# RP2350 register map
Vendor: Raspberry Pi; Series: RP; File version: 0.1
CPU: CM33 r1p0, little endian, MPU, FPU, DSP, VTOR, 4 interrupt priority bits, 52 interrupts, 8 SAU regions
Registers are 32-bit, read-write, reset 0x0 unless marked. A register's access mark holds for its fields unless they carry their own. Offsets are from the block's base; [hi:lo] are bit positions; {n}, {i} and the like mark numbered series.

## ACCESSCTRL (part 1 of 2) — Hardware access control registers
Base 0x40060000
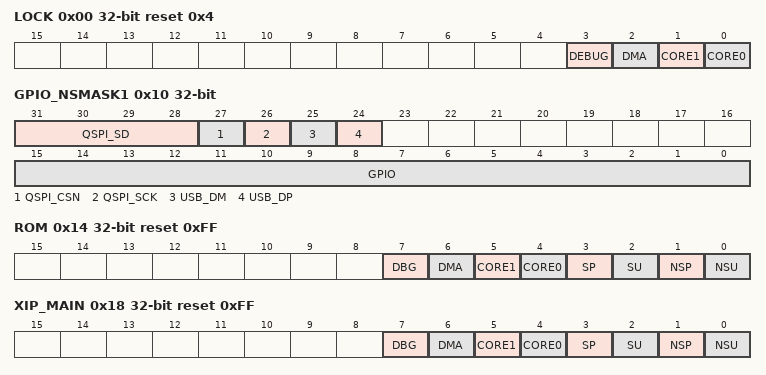
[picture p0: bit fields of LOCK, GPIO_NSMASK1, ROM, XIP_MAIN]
0x00 LOCK reset 0x4 — Once a LOCK bit is written to 1, ACCESSCTRL silently ignores writes from that master. LOCK is writable only by a Secure, Privileged processor or debugger. LOCK bits are only writable when their value is zero. Once set, they can never be cleared, except by a full reset of ACCESSCTRL Setting the LOCK bit does not affect whether an access raises a bus error. Unprivileged writes, or writes from the DMA, will continue to raise bus errors. All other accesses will continue not to.
  [3] DEBUG — Pre-defined description
  [2] DMA ro — Pre-defined description
  [1] CORE1 — Pre-defined description
  [0] CORE0 — Pre-defined description
0x04 FORCE_CORE_NS — Force core 1's bus accesses to always be Non-secure, no matter the core's internal state. Useful for schemes where one core is designated as the Non-secure core, since some peripherals may filter individual registers internally based on security state but not on master ID.
  [1] CORE1 — Pre-defined description
0x08 CFGRESET — Write 1 to reset all ACCESSCTRL configuration, except for the LOCK and FORCE_CORE_NS registers. This bit is used in the RP2350 bootrom to quickly restore ACCESSCTRL to a known state during the boot path. Note that, like all registers in ACCESSCTRL, this register is not writable when the writer's corresponding LOCK bit is set, therefore a master which has been locked out of ACCESSCTRL can not use the CFGRESET register to disturb its contents.
  [0] CFGRESET wo — Pre-defined description
0x0C GPIO_NSMASK0 — Control whether GPIO0...31 are accessible to Non-secure code. Writable only by a Secure, Privileged processor or debugger. 0 -> Secure access only 1 -> Secure + Non-secure access
  [31:0] GPIO_NSMASK0 — Pre-defined description
0x10 GPIO_NSMASK1 — Control whether GPIO32..47 are accessible to Non-secure code, and whether QSPI and USB bitbang are accessible through the Non-secure SIO. Writable only by a Secure, Privileged processor or debugger.
  [31:28] QSPI_SD — Pre-defined description
  [27] QSPI_CSN — Pre-defined description
  [26] QSPI_SCK — Pre-defined description
  [25] USB_DM — Pre-defined description
  [24] USB_DP — Pre-defined description
  [15:0] GPIO — Pre-defined description
0x14 ROM reset 0xFF — Control whether debugger, DMA, core 0 and core 1 can access ROM, and at what security/privilege levels they can do so. Defaults to fully open access. This register is writable only from a Secure, Privileged processor or debugger, with the exception of the NSU bit, which becomes Non-secure-Privileged-writable when the NSP bit is set.
  [7] DBG — If 1, ROM can be accessed by the debugger, at security/privilege levels permitted by SP/NSP/SU/NSU in this register.
  [6] DMA — If 1, ROM can be accessed by the DMA, at security/privilege levels permitted by SP/NSP/SU/NSU in this register.
  [5] CORE1 — If 1, ROM can be accessed by core 1, at security/privilege levels permitted by SP/NSP/SU/NSU in this register.
  [4] CORE0 — If 1, ROM can be accessed by core 0, at security/privilege levels permitted by SP/NSP/SU/NSU in this register.
  [3] SP — If 1, ROM can be accessed from a Secure, Privileged context.
  [2] SU — If 1, and SP is also set, ROM can be accessed from a Secure, Unprivileged context.
  [1] NSP — If 1, ROM can be accessed from a Non-secure, Privileged context.
  [0] NSU — If 1, and NSP is also set, ROM can be accessed from a Non-secure, Unprivileged context. This bit is writable from a Non-secure, Privileged context, if and only if the NSP bit is set.
0x18 XIP_MAIN reset 0xFF — Control whether debugger, DMA, core 0 and core 1 can access XIP_MAIN, and at what security/privilege levels they can do so. Defaults to fully open access. This register is writable only from a Secure, Privileged processor or debugger, with the exception of the NSU bit, which becomes Non-secure-Privileged-writable when the NSP bit is set.
  [7] DBG — If 1, XIP_MAIN can be accessed by the debugger, at security/privilege levels permitted by SP/NSP/SU/NSU in this register.
  [6] DMA — If 1, XIP_MAIN can be accessed by the DMA, at security/privilege levels permitted by SP/NSP/SU/NSU in this register.
  [5] CORE1 — If 1, XIP_MAIN can be accessed by core 1, at security/privilege levels permitted by SP/NSP/SU/NSU in this register.
  [4] CORE0 — If 1, XIP_MAIN can be accessed by core 0, at security/privilege levels permitted by SP/NSP/SU/NSU in this register.
  [3] SP — If 1, XIP_MAIN can be accessed from a Secure, Privileged context.
  [2] SU — If 1, and SP is also set, XIP_MAIN can be accessed from a Secure, Unprivileged context.
  [1] NSP — If 1, XIP_MAIN can be accessed from a Non-secure, Privileged context.
  [0] NSU — If 1, and NSP is also set, XIP_MAIN can be accessed from a Non-secure, Unprivileged context. This bit is writable from a Non-secure, Privileged context, if and only if the NSP bit is set.
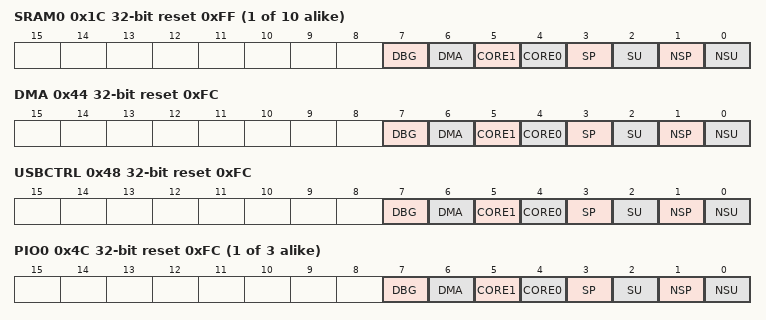
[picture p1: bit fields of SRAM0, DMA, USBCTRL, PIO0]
{0x1C+4i} SRAM{i} reset 0xFF (i=0..9) — Control whether debugger, DMA, core 0 and core 1 can access SRAM{i}, and at what security/privilege levels they can do so. Defaults to fully open access. This register is writable only from a Secure, Privileged processor or debugger, with the exception of the NSU bit, which becomes Non-secure-Privileged-writable when the NSP bit is set.
  [7] DBG — If 1, SRAM{i} can be accessed by the debugger, at security/privilege levels permitted by SP/NSP/SU/NSU in this register.
  [6] DMA — If 1, SRAM{i} can be accessed by the DMA, at security/privilege levels permitted by SP/NSP/SU/NSU in this register.
  [5] CORE1 — If 1, SRAM{i} can be accessed by core 1, at security/privilege levels permitted by SP/NSP/SU/NSU in this register.
  [4] CORE0 — If 1, SRAM{i} can be accessed by core 0, at security/privilege levels permitted by SP/NSP/SU/NSU in this register.
  [3] SP — If 1, SRAM{i} can be accessed from a Secure, Privileged context.
  [2] SU — If 1, and SP is also set, SRAM{i} can be accessed from a Secure, Unprivileged context.
  [1] NSP — If 1, SRAM{i} can be accessed from a Non-secure, Privileged context.
  [0] NSU — If 1, and NSP is also set, SRAM{i} can be accessed from a Non-secure, Unprivileged context. This bit is writable from a Non-secure, Privileged context, if and only if the NSP bit is set.
0x44 DMA reset 0xFC — Control whether debugger, DMA, core 0 and core 1 can access DMA, and at what security/privilege levels they can do so. Defaults to Secure access from any master. This register is writable only from a Secure, Privileged processor or debugger, with the exception of the NSU bit, which becomes Non-secure-Privileged-writable when the NSP bit is set.
  [7] DBG — If 1, DMA can be accessed by the debugger, at security/privilege levels permitted by SP/NSP/SU/NSU in this register.
  [6] DMA — If 1, DMA can be accessed by the DMA, at security/privilege levels permitted by SP/NSP/SU/NSU in this register.
  [5] CORE1 — If 1, DMA can be accessed by core 1, at security/privilege levels permitted by SP/NSP/SU/NSU in this register.
  [4] CORE0 — If 1, DMA can be accessed by core 0, at security/privilege levels permitted by SP/NSP/SU/NSU in this register.
  [3] SP — If 1, DMA can be accessed from a Secure, Privileged context.
  [2] SU — If 1, and SP is also set, DMA can be accessed from a Secure, Unprivileged context.
  [1] NSP — If 1, DMA can be accessed from a Non-secure, Privileged context.
  [0] NSU — If 1, and NSP is also set, DMA can be accessed from a Non-secure, Unprivileged context. This bit is writable from a Non-secure, Privileged context, if and only if the NSP bit is set.
0x48 USBCTRL reset 0xFC — Control whether debugger, DMA, core 0 and core 1 can access USBCTRL, and at what security/privilege levels they can do so. Defaults to Secure access from any master. This register is writable only from a Secure, Privileged processor or debugger, with the exception of the NSU bit, which becomes Non-secure-Privileged-writable when the NSP bit is set.
  [7] DBG — If 1, USBCTRL can be accessed by the debugger, at security/privilege levels permitted by SP/NSP/SU/NSU in this register.
  [6] DMA — If 1, USBCTRL can be accessed by the DMA, at security/privilege levels permitted by SP/NSP/SU/NSU in this register.
  [5] CORE1 — If 1, USBCTRL can be accessed by core 1, at security/privilege levels permitted by SP/NSP/SU/NSU in this register.
  [4] CORE0 — If 1, USBCTRL can be accessed by core 0, at security/privilege levels permitted by SP/NSP/SU/NSU in this register.
  [3] SP — If 1, USBCTRL can be accessed from a Secure, Privileged context.
  [2] SU — If 1, and SP is also set, USBCTRL can be accessed from a Secure, Unprivileged context.
  [1] NSP — If 1, USBCTRL can be accessed from a Non-secure, Privileged context.
  [0] NSU — If 1, and NSP is also set, USBCTRL can be accessed from a Non-secure, Unprivileged context. This bit is writable from a Non-secure, Privileged context, if and only if the NSP bit is set.
{0x4C+4i} PIO{i} reset 0xFC (i=0..2) — Control whether debugger, DMA, core 0 and core 1 can access PIO{i}, and at what security/privilege levels they can do so. Defaults to Secure access from any master. This register is writable only from a Secure, Privileged processor or debugger, with the exception of the NSU bit, which becomes Non-secure-Privileged-writable when the NSP bit is set.
  [7] DBG — If 1, PIO{i} can be accessed by the debugger, at security/privilege levels permitted by SP/NSP/SU/NSU in this register.
  [6] DMA — If 1, PIO{i} can be accessed by the DMA, at security/privilege levels permitted by SP/NSP/SU/NSU in this register.
  [5] CORE1 — If 1, PIO{i} can be accessed by core 1, at security/privilege levels permitted by SP/NSP/SU/NSU in this register.
  [4] CORE0 — If 1, PIO{i} can be accessed by core 0, at security/privilege levels permitted by SP/NSP/SU/NSU in this register.
  [3] SP — If 1, PIO{i} can be accessed from a Secure, Privileged context.
  [2] SU — If 1, and SP is also set, PIO{i} can be accessed from a Secure, Unprivileged context.
  [1] NSP — If 1, PIO{i} can be accessed from a Non-secure, Privileged context.
  [0] NSU — If 1, and NSP is also set, PIO{i} can be accessed from a Non-secure, Unprivileged context. This bit is writable from a Non-secure, Privileged context, if and only if the NSP bit is set.
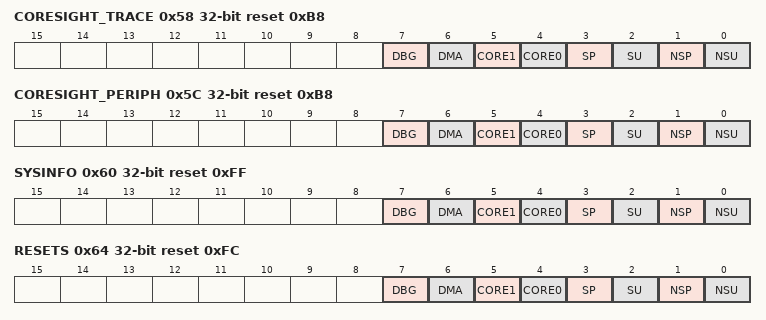
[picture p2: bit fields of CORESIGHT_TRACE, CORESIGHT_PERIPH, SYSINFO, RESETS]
0x58 CORESIGHT_TRACE reset 0xB8 — Control whether debugger, DMA, core 0 and core 1 can access CORESIGHT_TRACE, and at what security/privilege levels they can do so. Defaults to Secure, Privileged processor or debug access only. This register is writable only from a Secure, Privileged processor or debugger, with the exception of the NSU bit, which becomes Non-secure-Privileged-writable when the NSP bit is set.
  [7] DBG — If 1, CORESIGHT_TRACE can be accessed by the debugger, at security/privilege levels permitted by SP/NSP/SU/NSU in this register.
  [6] DMA — If 1, CORESIGHT_TRACE can be accessed by the DMA, at security/privilege levels permitted by SP/NSP/SU/NSU in this register.
  [5] CORE1 — If 1, CORESIGHT_TRACE can be accessed by core 1, at security/privilege levels permitted by SP/NSP/SU/NSU in this register.
  [4] CORE0 — If 1, CORESIGHT_TRACE can be accessed by core 0, at security/privilege levels permitted by SP/NSP/SU/NSU in this register.
  [3] SP — If 1, CORESIGHT_TRACE can be accessed from a Secure, Privileged context.
  [2] SU — If 1, and SP is also set, CORESIGHT_TRACE can be accessed from a Secure, Unprivileged context.
  [1] NSP — If 1, CORESIGHT_TRACE can be accessed from a Non-secure, Privileged context.
  [0] NSU — If 1, and NSP is also set, CORESIGHT_TRACE can be accessed from a Non-secure, Unprivileged context. This bit is writable from a Non-secure, Privileged context, if and only if the NSP bit is set.
0x5C CORESIGHT_PERIPH reset 0xB8 — Control whether debugger, DMA, core 0 and core 1 can access CORESIGHT_PERIPH, and at what security/privilege levels they can do so. Defaults to Secure, Privileged processor or debug access only. This register is writable only from a Secure, Privileged processor or debugger, with the exception of the NSU bit, which becomes Non-secure-Privileged-writable when the NSP bit is set.
  [7] DBG — If 1, CORESIGHT_PERIPH can be accessed by the debugger, at security/privilege levels permitted by SP/NSP/SU/NSU in this register.
  [6] DMA — If 1, CORESIGHT_PERIPH can be accessed by the DMA, at security/privilege levels permitted by SP/NSP/SU/NSU in this register.
  [5] CORE1 — If 1, CORESIGHT_PERIPH can be accessed by core 1, at security/privilege levels permitted by SP/NSP/SU/NSU in this register.
  [4] CORE0 — If 1, CORESIGHT_PERIPH can be accessed by core 0, at security/privilege levels permitted by SP/NSP/SU/NSU in this register.
  [3] SP — If 1, CORESIGHT_PERIPH can be accessed from a Secure, Privileged context.
  [2] SU — If 1, and SP is also set, CORESIGHT_PERIPH can be accessed from a Secure, Unprivileged context.
  [1] NSP — If 1, CORESIGHT_PERIPH can be accessed from a Non-secure, Privileged context.
  [0] NSU — If 1, and NSP is also set, CORESIGHT_PERIPH can be accessed from a Non-secure, Unprivileged context. This bit is writable from a Non-secure, Privileged context, if and only if the NSP bit is set.
0x60 SYSINFO reset 0xFF — Control whether debugger, DMA, core 0 and core 1 can access SYSINFO, and at what security/privilege levels they can do so. Defaults to fully open access. This register is writable only from a Secure, Privileged processor or debugger, with the exception of the NSU bit, which becomes Non-secure-Privileged-writable when the NSP bit is set.
  [7] DBG — If 1, SYSINFO can be accessed by the debugger, at security/privilege levels permitted by SP/NSP/SU/NSU in this register.
  [6] DMA — If 1, SYSINFO can be accessed by the DMA, at security/privilege levels permitted by SP/NSP/SU/NSU in this register.
  [5] CORE1 — If 1, SYSINFO can be accessed by core 1, at security/privilege levels permitted by SP/NSP/SU/NSU in this register.
  [4] CORE0 — If 1, SYSINFO can be accessed by core 0, at security/privilege levels permitted by SP/NSP/SU/NSU in this register.
  [3] SP — If 1, SYSINFO can be accessed from a Secure, Privileged context.
  [2] SU — If 1, and SP is also set, SYSINFO can be accessed from a Secure, Unprivileged context.
  [1] NSP — If 1, SYSINFO can be accessed from a Non-secure, Privileged context.
  [0] NSU — If 1, and NSP is also set, SYSINFO can be accessed from a Non-secure, Unprivileged context. This bit is writable from a Non-secure, Privileged context, if and only if the NSP bit is set.
0x64 RESETS reset 0xFC — Control whether debugger, DMA, core 0 and core 1 can access RESETS, and at what security/privilege levels they can do so. Defaults to Secure access from any master. This register is writable only from a Secure, Privileged processor or debugger, with the exception of the NSU bit, which becomes Non-secure-Privileged-writable when the NSP bit is set.
  [7] DBG — If 1, RESETS can be accessed by the debugger, at security/privilege levels permitted by SP/NSP/SU/NSU in this register.
  [6] DMA — If 1, RESETS can be accessed by the DMA, at security/privilege levels permitted by SP/NSP/SU/NSU in this register.
  [5] CORE1 — If 1, RESETS can be accessed by core 1, at security/privilege levels permitted by SP/NSP/SU/NSU in this register.
  [4] CORE0 — If 1, RESETS can be accessed by core 0, at security/privilege levels permitted by SP/NSP/SU/NSU in this register.
  [3] SP — If 1, RESETS can be accessed from a Secure, Privileged context.
  [2] SU — If 1, and SP is also set, RESETS can be accessed from a Secure, Unprivileged context.
  [1] NSP — If 1, RESETS can be accessed from a Non-secure, Privileged context.
  [0] NSU — If 1, and NSP is also set, RESETS can be accessed from a Non-secure, Unprivileged context. This bit is writable from a Non-secure, Privileged context, if and only if the NSP bit is set.
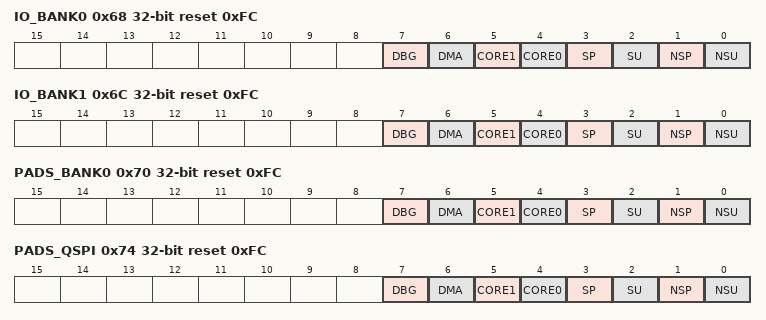
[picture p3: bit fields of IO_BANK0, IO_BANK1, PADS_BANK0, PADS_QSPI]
0x68 IO_BANK0 reset 0xFC — Control whether debugger, DMA, core 0 and core 1 can access IO_BANK0, and at what security/privilege levels they can do so. Defaults to Secure access from any master. This register is writable only from a Secure, Privileged processor or debugger, with the exception of the NSU bit, which becomes Non-secure-Privileged-writable when the NSP bit is set.
  [7] DBG — If 1, IO_BANK0 can be accessed by the debugger, at security/privilege levels permitted by SP/NSP/SU/NSU in this register.
  [6] DMA — If 1, IO_BANK0 can be accessed by the DMA, at security/privilege levels permitted by SP/NSP/SU/NSU in this register.
  [5] CORE1 — If 1, IO_BANK0 can be accessed by core 1, at security/privilege levels permitted by SP/NSP/SU/NSU in this register.
  [4] CORE0 — If 1, IO_BANK0 can be accessed by core 0, at security/privilege levels permitted by SP/NSP/SU/NSU in this register.
  [3] SP — If 1, IO_BANK0 can be accessed from a Secure, Privileged context.
  [2] SU — If 1, and SP is also set, IO_BANK0 can be accessed from a Secure, Unprivileged context.
  [1] NSP — If 1, IO_BANK0 can be accessed from a Non-secure, Privileged context.
  [0] NSU — If 1, and NSP is also set, IO_BANK0 can be accessed from a Non-secure, Unprivileged context. This bit is writable from a Non-secure, Privileged context, if and only if the NSP bit is set.
0x6C IO_BANK1 reset 0xFC — Control whether debugger, DMA, core 0 and core 1 can access IO_BANK1, and at what security/privilege levels they can do so. Defaults to Secure access from any master. This register is writable only from a Secure, Privileged processor or debugger, with the exception of the NSU bit, which becomes Non-secure-Privileged-writable when the NSP bit is set.
  [7] DBG — If 1, IO_BANK1 can be accessed by the debugger, at security/privilege levels permitted by SP/NSP/SU/NSU in this register.
  [6] DMA — If 1, IO_BANK1 can be accessed by the DMA, at security/privilege levels permitted by SP/NSP/SU/NSU in this register.
  [5] CORE1 — If 1, IO_BANK1 can be accessed by core 1, at security/privilege levels permitted by SP/NSP/SU/NSU in this register.
  [4] CORE0 — If 1, IO_BANK1 can be accessed by core 0, at security/privilege levels permitted by SP/NSP/SU/NSU in this register.
  [3] SP — If 1, IO_BANK1 can be accessed from a Secure, Privileged context.
  [2] SU — If 1, and SP is also set, IO_BANK1 can be accessed from a Secure, Unprivileged context.
  [1] NSP — If 1, IO_BANK1 can be accessed from a Non-secure, Privileged context.
  [0] NSU — If 1, and NSP is also set, IO_BANK1 can be accessed from a Non-secure, Unprivileged context. This bit is writable from a Non-secure, Privileged context, if and only if the NSP bit is set.
0x70 PADS_BANK0 reset 0xFC — Control whether debugger, DMA, core 0 and core 1 can access PADS_BANK0, and at what security/privilege levels they can do so. Defaults to Secure access from any master. This register is writable only from a Secure, Privileged processor or debugger, with the exception of the NSU bit, which becomes Non-secure-Privileged-writable when the NSP bit is set.
  [7] DBG — If 1, PADS_BANK0 can be accessed by the debugger, at security/privilege levels permitted by SP/NSP/SU/NSU in this register.
  [6] DMA — If 1, PADS_BANK0 can be accessed by the DMA, at security/privilege levels permitted by SP/NSP/SU/NSU in this register.
  [5] CORE1 — If 1, PADS_BANK0 can be accessed by core 1, at security/privilege levels permitted by SP/NSP/SU/NSU in this register.
  [4] CORE0 — If 1, PADS_BANK0 can be accessed by core 0, at security/privilege levels permitted by SP/NSP/SU/NSU in this register.
  [3] SP — If 1, PADS_BANK0 can be accessed from a Secure, Privileged context.
  [2] SU — If 1, and SP is also set, PADS_BANK0 can be accessed from a Secure, Unprivileged context.
  [1] NSP — If 1, PADS_BANK0 can be accessed from a Non-secure, Privileged context.
  [0] NSU — If 1, and NSP is also set, PADS_BANK0 can be accessed from a Non-secure, Unprivileged context. This bit is writable from a Non-secure, Privileged context, if and only if the NSP bit is set.
0x74 PADS_QSPI reset 0xFC — Control whether debugger, DMA, core 0 and core 1 can access PADS_QSPI, and at what security/privilege levels they can do so. Defaults to Secure access from any master. This register is writable only from a Secure, Privileged processor or debugger, with the exception of the NSU bit, which becomes Non-secure-Privileged-writable when the NSP bit is set.
  [7] DBG — If 1, PADS_QSPI can be accessed by the debugger, at security/privilege levels permitted by SP/NSP/SU/NSU in this register.
  [6] DMA — If 1, PADS_QSPI can be accessed by the DMA, at security/privilege levels permitted by SP/NSP/SU/NSU in this register.
  [5] CORE1 — If 1, PADS_QSPI can be accessed by core 1, at security/privilege levels permitted by SP/NSP/SU/NSU in this register.
  [4] CORE0 — If 1, PADS_QSPI can be accessed by core 0, at security/privilege levels permitted by SP/NSP/SU/NSU in this register.
  [3] SP — If 1, PADS_QSPI can be accessed from a Secure, Privileged context.
  [2] SU — If 1, and SP is also set, PADS_QSPI can be accessed from a Secure, Unprivileged context.
  [1] NSP — If 1, PADS_QSPI can be accessed from a Non-secure, Privileged context.
  [0] NSU — If 1, and NSP is also set, PADS_QSPI can be accessed from a Non-secure, Unprivileged context. This bit is writable from a Non-secure, Privileged context, if and only if the NSP bit is set.
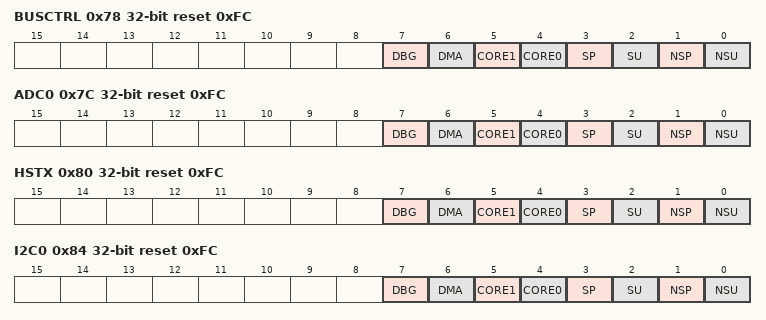
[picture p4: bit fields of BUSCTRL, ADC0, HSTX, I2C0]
0x78 BUSCTRL reset 0xFC — Control whether debugger, DMA, core 0 and core 1 can access BUSCTRL, and at what security/privilege levels they can do so. Defaults to Secure access from any master. This register is writable only from a Secure, Privileged processor or debugger, with the exception of the NSU bit, which becomes Non-secure-Privileged-writable when the NSP bit is set.
  [7] DBG — If 1, BUSCTRL can be accessed by the debugger, at security/privilege levels permitted by SP/NSP/SU/NSU in this register.
  [6] DMA — If 1, BUSCTRL can be accessed by the DMA, at security/privilege levels permitted by SP/NSP/SU/NSU in this register.
  [5] CORE1 — If 1, BUSCTRL can be accessed by core 1, at security/privilege levels permitted by SP/NSP/SU/NSU in this register.
  [4] CORE0 — If 1, BUSCTRL can be accessed by core 0, at security/privilege levels permitted by SP/NSP/SU/NSU in this register.
  [3] SP — If 1, BUSCTRL can be accessed from a Secure, Privileged context.
  [2] SU — If 1, and SP is also set, BUSCTRL can be accessed from a Secure, Unprivileged context.
  [1] NSP — If 1, BUSCTRL can be accessed from a Non-secure, Privileged context.
  [0] NSU — If 1, and NSP is also set, BUSCTRL can be accessed from a Non-secure, Unprivileged context. This bit is writable from a Non-secure, Privileged context, if and only if the NSP bit is set.
0x7C ADC0 reset 0xFC — Control whether debugger, DMA, core 0 and core 1 can access ADC0, and at what security/privilege levels they can do so. Defaults to Secure access from any master. This register is writable only from a Secure, Privileged processor or debugger, with the exception of the NSU bit, which becomes Non-secure-Privileged-writable when the NSP bit is set.
  [7] DBG — If 1, ADC0 can be accessed by the debugger, at security/privilege levels permitted by SP/NSP/SU/NSU in this register.
  [6] DMA — If 1, ADC0 can be accessed by the DMA, at security/privilege levels permitted by SP/NSP/SU/NSU in this register.
  [5] CORE1 — If 1, ADC0 can be accessed by core 1, at security/privilege levels permitted by SP/NSP/SU/NSU in this register.
  [4] CORE0 — If 1, ADC0 can be accessed by core 0, at security/privilege levels permitted by SP/NSP/SU/NSU in this register.
  [3] SP — If 1, ADC0 can be accessed from a Secure, Privileged context.
  [2] SU — If 1, and SP is also set, ADC0 can be accessed from a Secure, Unprivileged context.
  [1] NSP — If 1, ADC0 can be accessed from a Non-secure, Privileged context.
  [0] NSU — If 1, and NSP is also set, ADC0 can be accessed from a Non-secure, Unprivileged context. This bit is writable from a Non-secure, Privileged context, if and only if the NSP bit is set.
0x80 HSTX reset 0xFC — Control whether debugger, DMA, core 0 and core 1 can access HSTX, and at what security/privilege levels they can do so. Defaults to Secure access from any master. This register is writable only from a Secure, Privileged processor or debugger, with the exception of the NSU bit, which becomes Non-secure-Privileged-writable when the NSP bit is set.
  [7] DBG — If 1, HSTX can be accessed by the debugger, at security/privilege levels permitted by SP/NSP/SU/NSU in this register.
  [6] DMA — If 1, HSTX can be accessed by the DMA, at security/privilege levels permitted by SP/NSP/SU/NSU in this register.
  [5] CORE1 — If 1, HSTX can be accessed by core 1, at security/privilege levels permitted by SP/NSP/SU/NSU in this register.
  [4] CORE0 — If 1, HSTX can be accessed by core 0, at security/privilege levels permitted by SP/NSP/SU/NSU in this register.
  [3] SP — If 1, HSTX can be accessed from a Secure, Privileged context.
  [2] SU — If 1, and SP is also set, HSTX can be accessed from a Secure, Unprivileged context.
  [1] NSP — If 1, HSTX can be accessed from a Non-secure, Privileged context.
  [0] NSU — If 1, and NSP is also set, HSTX can be accessed from a Non-secure, Unprivileged context. This bit is writable from a Non-secure, Privileged context, if and only if the NSP bit is set.
0x84 I2C0 reset 0xFC — Control whether debugger, DMA, core 0 and core 1 can access I2C0, and at what security/privilege levels they can do so. Defaults to Secure access from any master. This register is writable only from a Secure, Privileged processor or debugger, with the exception of the NSU bit, which becomes Non-secure-Privileged-writable when the NSP bit is set.
  [7] DBG — If 1, I2C0 can be accessed by the debugger, at security/privilege levels permitted by SP/NSP/SU/NSU in this register.
  [6] DMA — If 1, I2C0 can be accessed by the DMA, at security/privilege levels permitted by SP/NSP/SU/NSU in this register.
  [5] CORE1 — If 1, I2C0 can be accessed by core 1, at security/privilege levels permitted by SP/NSP/SU/NSU in this register.
  [4] CORE0 — If 1, I2C0 can be accessed by core 0, at security/privilege levels permitted by SP/NSP/SU/NSU in this register.
  [3] SP — If 1, I2C0 can be accessed from a Secure, Privileged context.
  [2] SU — If 1, and SP is also set, I2C0 can be accessed from a Secure, Unprivileged context.
  [1] NSP — If 1, I2C0 can be accessed from a Non-secure, Privileged context.
  [0] NSU — If 1, and NSP is also set, I2C0 can be accessed from a Non-secure, Unprivileged context. This bit is writable from a Non-secure, Privileged context, if and only if the NSP bit is set.
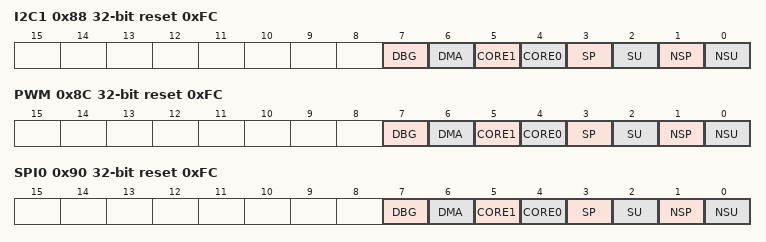
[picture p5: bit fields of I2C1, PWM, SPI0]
0x88 I2C1 reset 0xFC — Control whether debugger, DMA, core 0 and core 1 can access I2C1, and at what security/privilege levels they can do so. Defaults to Secure access from any master. This register is writable only from a Secure, Privileged processor or debugger, with the exception of the NSU bit, which becomes Non-secure-Privileged-writable when the NSP bit is set.
  [7] DBG — If 1, I2C1 can be accessed by the debugger, at security/privilege levels permitted by SP/NSP/SU/NSU in this register.
  [6] DMA — If 1, I2C1 can be accessed by the DMA, at security/privilege levels permitted by SP/NSP/SU/NSU in this register.
  [5] CORE1 — If 1, I2C1 can be accessed by core 1, at security/privilege levels permitted by SP/NSP/SU/NSU in this register.
  [4] CORE0 — If 1, I2C1 can be accessed by core 0, at security/privilege levels permitted by SP/NSP/SU/NSU in this register.
  [3] SP — If 1, I2C1 can be accessed from a Secure, Privileged context.
  [2] SU — If 1, and SP is also set, I2C1 can be accessed from a Secure, Unprivileged context.
  [1] NSP — If 1, I2C1 can be accessed from a Non-secure, Privileged context.
  [0] NSU — If 1, and NSP is also set, I2C1 can be accessed from a Non-secure, Unprivileged context. This bit is writable from a Non-secure, Privileged context, if and only if the NSP bit is set.
0x8C PWM reset 0xFC — Control whether debugger, DMA, core 0 and core 1 can access PWM, and at what security/privilege levels they can do so. Defaults to Secure access from any master. This register is writable only from a Secure, Privileged processor or debugger, with the exception of the NSU bit, which becomes Non-secure-Privileged-writable when the NSP bit is set.
  [7] DBG — If 1, PWM can be accessed by the debugger, at security/privilege levels permitted by SP/NSP/SU/NSU in this register.
  [6] DMA — If 1, PWM can be accessed by the DMA, at security/privilege levels permitted by SP/NSP/SU/NSU in this register.
  [5] CORE1 — If 1, PWM can be accessed by core 1, at security/privilege levels permitted by SP/NSP/SU/NSU in this register.
  [4] CORE0 — If 1, PWM can be accessed by core 0, at security/privilege levels permitted by SP/NSP/SU/NSU in this register.
  [3] SP — If 1, PWM can be accessed from a Secure, Privileged context.
  [2] SU — If 1, and SP is also set, PWM can be accessed from a Secure, Unprivileged context.
  [1] NSP — If 1, PWM can be accessed from a Non-secure, Privileged context.
  [0] NSU — If 1, and NSP is also set, PWM can be accessed from a Non-secure, Unprivileged context. This bit is writable from a Non-secure, Privileged context, if and only if the NSP bit is set.
0x90 SPI0 reset 0xFC — Control whether debugger, DMA, core 0 and core 1 can access SPI0, and at what security/privilege levels they can do so. Defaults to Secure access from any master. This register is writable only from a Secure, Privileged processor or debugger, with the exception of the NSU bit, which becomes Non-secure-Privileged-writable when the NSP bit is set.
  [7] DBG — If 1, SPI0 can be accessed by the debugger, at security/privilege levels permitted by SP/NSP/SU/NSU in this register.
  [6] DMA — If 1, SPI0 can be accessed by the DMA, at security/privilege levels permitted by SP/NSP/SU/NSU in this register.
  [5] CORE1 — If 1, SPI0 can be accessed by core 1, at security/privilege levels permitted by SP/NSP/SU/NSU in this register.
  [4] CORE0 — If 1, SPI0 can be accessed by core 0, at security/privilege levels permitted by SP/NSP/SU/NSU in this register.
  [3] SP — If 1, SPI0 can be accessed from a Secure, Privileged context.
  [2] SU — If 1, and SP is also set, SPI0 can be accessed from a Secure, Unprivileged context.
  [1] NSP — If 1, SPI0 can be accessed from a Non-secure, Privileged context.
  [0] NSU — If 1, and NSP is also set, SPI0 can be accessed from a Non-secure, Unprivileged context. This bit is writable from a Non-secure, Privileged context, if and only if the NSP bit is set.
